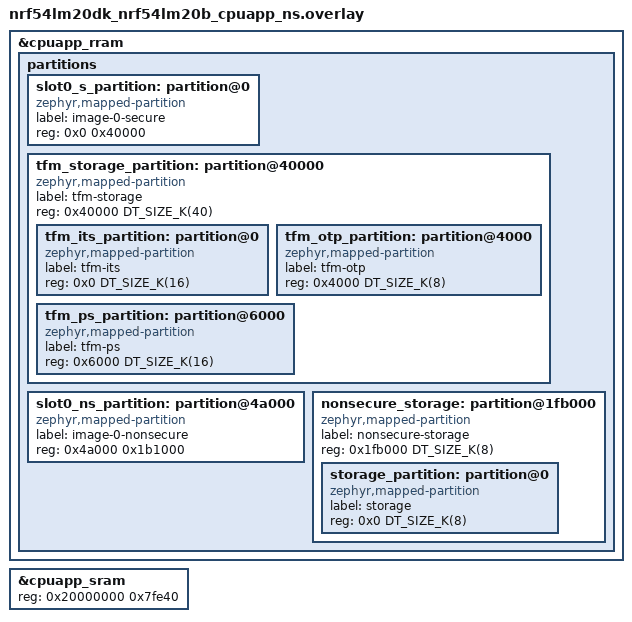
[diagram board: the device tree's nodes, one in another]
/*
 * Copyright (c) 2026 Nordic Semiconductor ASA
 *
 * SPDX-License-Identifier: LicenseRef-Nordic-5-Clause
 */

/delete-node/ &slot0_partition;
/delete-node/ &tfm_ps_partition;
/delete-node/ &tfm_its_partition;
/delete-node/ &tfm_otp_partition;
/delete-node/ &slot0_ns_partition;
/delete-node/ &storage_partition;

&cpuapp_rram {
	partitions {
		slot0_s_partition: partition@0 {
			compatible = "zephyr,mapped-partition";
			label = "image-0-secure";
			reg = <0x0 0x40000>;
		};

		tfm_storage_partition: partition@40000 {
			compatible = "zephyr,mapped-partition";
			label = "tfm-storage";
			reg = <0x40000 DT_SIZE_K(40)>;
			ranges = <0x0 0x40000 DT_SIZE_K(40)>;
			#address-cells = <1>;
			#size-cells = <1>;

			tfm_its_partition: partition@0 {
				compatible = "zephyr,mapped-partition";
				label = "tfm-its";
				reg = <0x0 DT_SIZE_K(16)>;
			};

			tfm_otp_partition: partition@4000 {
				compatible = "zephyr,mapped-partition";
				label = "tfm-otp";
				reg = <0x4000 DT_SIZE_K(8)>;
			};

			tfm_ps_partition: partition@6000 {
				compatible = "zephyr,mapped-partition";
				label = "tfm-ps";
				reg = <0x6000 DT_SIZE_K(16)>;
			};
		};

		slot0_ns_partition: partition@4a000 {
			compatible = "zephyr,mapped-partition";
			label = "image-0-nonsecure";
			reg = <0x4a000 0x1b1000>;
		};

		nonsecure_storage: partition@1fb000 {
			compatible = "zephyr,mapped-partition";
			label = "nonsecure-storage";
			reg = <0x1fb000 DT_SIZE_K(8)>;
			ranges = <0x0 0x1fb000 DT_SIZE_K(8)>;
			#address-cells = <1>;
			#size-cells = <1>;

			storage_partition: partition@0 {
				compatible = "zephyr,mapped-partition";
				label = "storage";
				reg = <0x0 DT_SIZE_K(8)>;
			};
		};
	};
};

&cpuapp_sram {
	reg = <0x20000000 0x7fe40>;
	ranges = <0x0 0x20000000 0x7fe40>;
};
